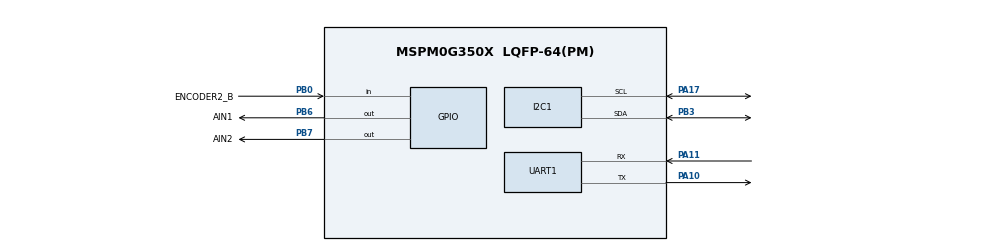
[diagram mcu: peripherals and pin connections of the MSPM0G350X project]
/**
 * @cliArgs --device "MSPM0G350X" --part "Default" --package "LQFP-64(PM)" --product "mspm0_sdk@2.05.00.05"
 * @versions {"tool":"1.24.0+4110"}
 */

/**
 * Import the modules used in this configuration.
 */
const CAPTURE  = scripting.addModule("/ti/driverlib/CAPTURE", {}, false);
const CAPTURE1 = CAPTURE.addInstance();
const CAPTURE2 = CAPTURE.addInstance();
const CAPTURE3 = CAPTURE.addInstance();
const CAPTURE4 = CAPTURE.addInstance();
const GPIO     = scripting.addModule("/ti/driverlib/GPIO", {}, false);
const GPIO1    = GPIO.addInstance();
const GPIO2    = GPIO.addInstance();
const GPIO3    = GPIO.addInstance();
const GPIO4    = GPIO.addInstance();
const GPIO5    = GPIO.addInstance();
const I2C      = scripting.addModule("/ti/driverlib/I2C", {}, false);
const I2C1     = I2C.addInstance();
const PWM      = scripting.addModule("/ti/driverlib/PWM", {}, false);
const PWM1     = PWM.addInstance();
const PWM2     = PWM.addInstance();
const SYSCTL   = scripting.addModule("/ti/driverlib/SYSCTL");
const SYSTICK  = scripting.addModule("/ti/driverlib/SYSTICK");
const TIMER    = scripting.addModule("/ti/driverlib/TIMER", {}, false);
const TIMER1   = TIMER.addInstance();
const UART     = scripting.addModule("/ti/driverlib/UART", {}, false);
const UART1    = UART.addInstance();

/**
 * Write custom configuration values to the imported modules.
 */
CAPTURE1.$name                              = "ENCODER1_A";
CAPTURE1.timerPeriod                        = "1ms";
CAPTURE1.timerStartTimer                    = true;
CAPTURE1.interrupts                         = ["CC0_DN"];
CAPTURE1.ccp0PinConfig.hideOutputInversion  = scripting.forceWrite(false);
CAPTURE1.ccp0PinConfig.onlyInternalResistor = scripting.forceWrite(false);
CAPTURE1.ccp0PinConfig.passedPeripheralType = scripting.forceWrite("Digital");
CAPTURE1.ccp0PinConfig.$name                = "ti_driverlib_gpio_GPIOPinGeneric9";

const Board = scripting.addModule("/ti/driverlib/Board", {}, false);

CAPTURE2.$name                              = "ENCODER2_A";
CAPTURE2.timerPeriod                        = "1ms";
CAPTURE2.timerStartTimer                    = true;
CAPTURE2.interrupts                         = ["CC0_DN"];
CAPTURE2.ccp0PinConfig.hideOutputInversion  = scripting.forceWrite(false);
CAPTURE2.ccp0PinConfig.onlyInternalResistor = scripting.forceWrite(false);
CAPTURE2.ccp0PinConfig.passedPeripheralType = scripting.forceWrite("Digital");
CAPTURE2.ccp0PinConfig.$name                = "ti_driverlib_gpio_GPIOPinGeneric10";

CAPTURE3.$name                              = "ENCODER3_A";
CAPTURE3.timerPeriod                        = "1ms";
CAPTURE3.timerStartTimer                    = true;
CAPTURE3.interrupts                         = ["CC0_DN"];
CAPTURE3.ccp0PinConfig.hideOutputInversion  = scripting.forceWrite(false);
CAPTURE3.ccp0PinConfig.onlyInternalResistor = scripting.forceWrite(false);
CAPTURE3.ccp0PinConfig.passedPeripheralType = scripting.forceWrite("Digital");
CAPTURE3.ccp0PinConfig.$name                = "ti_driverlib_gpio_GPIOPinGeneric11";

CAPTURE4.$name                              = "ENCODER4_A";
CAPTURE4.timerPeriod                        = "1ms";
CAPTURE4.timerStartTimer                    = true;
CAPTURE4.interrupts                         = ["CC0_DN"];
CAPTURE4.ccp0PinConfig.hideOutputInversion  = scripting.forceWrite(false);
CAPTURE4.ccp0PinConfig.onlyInternalResistor = scripting.forceWrite(false);
CAPTURE4.ccp0PinConfig.passedPeripheralType = scripting.forceWrite("Digital");
CAPTURE4.ccp0PinConfig.$name                = "ti_driverlib_gpio_GPIOPinGeneric12";

GPIO1.$name                              = "INF_INPUT";
GPIO1.port                               = "PORTA";
GPIO1.associatedPins.create(4);
GPIO1.associatedPins[0].direction        = "INPUT";
GPIO1.associatedPins[0].$name            = "L1";
GPIO1.associatedPins[0].internalResistor = "PULL_UP";
GPIO1.associatedPins[0].assignedPin      = "25";
GPIO1.associatedPins[1].$name            = "L2";
GPIO1.associatedPins[1].direction        = "INPUT";
GPIO1.associatedPins[1].internalResistor = "PULL_UP";
GPIO1.associatedPins[1].assignedPin      = "24";
GPIO1.associatedPins[2].$name            = "R2";
GPIO1.associatedPins[2].direction        = "INPUT";
GPIO1.associatedPins[2].internalResistor = "PULL_UP";
GPIO1.associatedPins[2].assignedPin      = "23";
GPIO1.associatedPins[3].$name            = "R1";
GPIO1.associatedPins[3].direction        = "INPUT";
GPIO1.associatedPins[3].internalResistor = "PULL_UP";
GPIO1.associatedPins[3].assignedPin      = "26";

GPIO2.$name                              = "LED";
GPIO2.port                               = "PORTB";
GPIO2.associatedPins[0].$name            = "LED1";
GPIO2.associatedPins[0].internalResistor = "PULL_DOWN";
GPIO2.associatedPins[0].assignedPin      = "2";

GPIO3.$name                              = "KEY";
GPIO3.port                               = "PORTA";
GPIO3.associatedPins[0].$name            = "KEY1";
GPIO3.associatedPins[0].direction        = "INPUT";
GPIO3.associatedPins[0].internalResistor = "PULL_DOWN";
GPIO3.associatedPins[0].assignedPin      = "18";

GPIO4.$name                         = "MOTORS";
GPIO4.port                          = "PORTB";
GPIO4.associatedPins.create(8);
GPIO4.associatedPins[0].$name       = "AIN1";
GPIO4.associatedPins[0].assignedPin = "6";
GPIO4.associatedPins[0].pin.$assign = "PB6";
GPIO4.associatedPins[1].$name       = "AIN2";
GPIO4.associatedPins[1].assignedPin = "7";
GPIO4.associatedPins[1].pin.$assign = "PB7";
GPIO4.associatedPins[2].$name       = "BIN1";
GPIO4.associatedPins[2].assignedPin = "8";
GPIO4.associatedPins[3].$name       = "BIN2";
GPIO4.associatedPins[3].assignedPin = "9";
GPIO4.associatedPins[4].$name       = "CIN1";
GPIO4.associatedPins[5].$name       = "CIN2";
GPIO4.associatedPins[6].$name       = "DIN1";
GPIO4.associatedPins[7].$name       = "DIN2";

GPIO5.$name                          = "GPIO_ENCODER";
GPIO5.associatedPins.create(4);
GPIO5.associatedPins[0].$name        = "ENCODER1_B";
GPIO5.associatedPins[0].direction    = "INPUT";
GPIO5.associatedPins[0].assignedPort = "PORTA";
GPIO5.associatedPins[0].assignedPin  = "7";
GPIO5.associatedPins[1].$name        = "ENCODER2_B";
GPIO5.associatedPins[1].direction    = "INPUT";
GPIO5.associatedPins[1].assignedPort = "PORTB";
GPIO5.associatedPins[1].assignedPin  = "0";
GPIO5.associatedPins[1].pin.$assign  = "PB0";
GPIO5.associatedPins[2].$name        = "ENCODER3_B";
GPIO5.associatedPins[2].direction    = "INPUT";
GPIO5.associatedPins[2].assignedPort = "PORTB";
GPIO5.associatedPins[2].assignedPin  = "18";
GPIO5.associatedPins[3].$name        = "ENCODER4_B";
GPIO5.associatedPins[3].direction    = "INPUT";
GPIO5.associatedPins[3].assignedPort = "PORTA";
GPIO5.associatedPins[3].assignedPin  = "27";

I2C1.$name                             = "I2C_SCR";
I2C1.peripheral.sdaPin.$assign         = "PB3";
I2C1.peripheral.sclPin.$assign         = "PA17";
I2C1.sdaPinConfig.hideOutputInversion  = scripting.forceWrite(false);
I2C1.sdaPinConfig.onlyInternalResistor = scripting.forceWrite(false);
I2C1.sdaPinConfig.passedPeripheralType = scripting.forceWrite("Digital");
I2C1.sdaPinConfig.$name                = "ti_driverlib_gpio_GPIOPinGeneric7";
I2C1.sclPinConfig.hideOutputInversion  = scripting.forceWrite(false);
I2C1.sclPinConfig.onlyInternalResistor = scripting.forceWrite(false);
I2C1.sclPinConfig.passedPeripheralType = scripting.forceWrite("Digital");
I2C1.sclPinConfig.$name                = "ti_driverlib_gpio_GPIOPinGeneric8";

PWM1.$name                              = "PWM_MOTOR";
PWM1.ccIndex                            = [0,1,2,3];
PWM1.timerCount                         = 3200;
PWM1.PWM_CHANNEL_0.$name                = "ti_driverlib_pwm_PWMTimerCC0";
PWM1.PWM_CHANNEL_1.$name                = "ti_driverlib_pwm_PWMTimerCC1";
PWM1.ccp0PinConfig.direction            = scripting.forceWrite("OUTPUT");
PWM1.ccp0PinConfig.hideOutputInversion  = scripting.forceWrite(false);
PWM1.ccp0PinConfig.onlyInternalResistor = scripting.forceWrite(false);
PWM1.ccp0PinConfig.passedPeripheralType = scripting.forceWrite("Digital");
PWM1.ccp0PinConfig.$name                = "ti_driverlib_gpio_GPIOPinGeneric2";
PWM1.ccp1PinConfig.direction            = scripting.forceWrite("OUTPUT");
PWM1.ccp1PinConfig.hideOutputInversion  = scripting.forceWrite(false);
PWM1.ccp1PinConfig.onlyInternalResistor = scripting.forceWrite(false);
PWM1.ccp1PinConfig.passedPeripheralType = scripting.forceWrite("Digital");
PWM1.ccp1PinConfig.$name                = "ti_driverlib_gpio_GPIOPinGeneric3";
PWM1.peripheral.$assign                 = "TIMA0";
PWM1.PWM_CHANNEL_2.$name                = "ti_driverlib_pwm_PWMTimerCC2";
PWM1.PWM_CHANNEL_3.$name                = "ti_driverlib_pwm_PWMTimerCC3";
PWM1.ccp2PinConfig.$name                = "ti_driverlib_gpio_GPIOPinGeneric4";
PWM1.ccp3PinConfig.$name                = "ti_driverlib_gpio_GPIOPinGeneric5";

PWM2.$name                              = "PWM_SERVO";
PWM2.clockDivider                       = 8;
PWM2.timerCount                         = 80000;
PWM2.ccIndex                            = [0];
PWM2.PWM_CHANNEL_0.$name                = "ti_driverlib_pwm_PWMTimerCC4";
PWM2.ccp0PinConfig.direction            = scripting.forceWrite("OUTPUT");
PWM2.ccp0PinConfig.hideOutputInversion  = scripting.forceWrite(false);
PWM2.ccp0PinConfig.onlyInternalResistor = scripting.forceWrite(false);
PWM2.ccp0PinConfig.passedPeripheralType = scripting.forceWrite("Digital");
PWM2.ccp0PinConfig.$name                = "ti_driverlib_gpio_GPIOPinGeneric6";
PWM2.peripheral.$assign                 = "TIMG12";

SYSCTL.forceDefaultClkConfig = true;

SYSTICK.periodEnable    = true;
SYSTICK.period          = 32000;
SYSTICK.interruptEnable = true;
SYSTICK.systickEnable   = true;

TIMER1.$name            = "CLOCK";
TIMER1.timerClkPrescale = 5;
TIMER1.timerMode        = "PERIODIC";
TIMER1.timerPeriod      = "10ms";
TIMER1.timerStartTimer  = true;
TIMER1.interrupts       = ["ZERO"];

UART1.$name                    = "UART_0";
UART1.targetBaudRate           = 115200;
UART1.peripheral.rxPin.$assign = "PA11";
UART1.peripheral.txPin.$assign = "PA10";
UART1.txPinConfig.$name        = "ti_driverlib_gpio_GPIOPinGeneric0";
UART1.rxPinConfig.$name        = "ti_driverlib_gpio_GPIOPinGeneric1";

/**
 * Pinmux solution for unlocked pins/peripherals. This ensures that minor changes to the automatic solver in a future
 * version of the tool will not impact the pinmux you originally saw.  These lines can be completely deleted in order to
 * re-solve from scratch.
 */
CAPTURE1.peripheral.$suggestSolution         = "TIMG8";
CAPTURE1.peripheral.ccp0Pin.$suggestSolution = "PA29";
Board.peripheral.$suggestSolution            = "DEBUGSS";
Board.peripheral.swclkPin.$suggestSolution   = "PA20";
Board.peripheral.swdioPin.$suggestSolution   = "PA19";
CAPTURE2.peripheral.$suggestSolution         = "TIMG7";
CAPTURE2.peripheral.ccp0Pin.$suggestSolution = "PA28";
CAPTURE3.peripheral.$suggestSolution         = "TIMG6";
CAPTURE3.peripheral.ccp0Pin.$suggestSolution = "PA21";
CAPTURE4.peripheral.$suggestSolution         = "TIMG0";
CAPTURE4.peripheral.ccp0Pin.$suggestSolution = "PA5";
GPIO1.associatedPins[0].pin.$suggestSolution = "PA25";
GPIO1.associatedPins[1].pin.$suggestSolution = "PA24";
GPIO1.associatedPins[2].pin.$suggestSolution = "PA23";
GPIO1.associatedPins[3].pin.$suggestSolution = "PA26";
GPIO2.associatedPins[0].pin.$suggestSolution = "PB2";
GPIO3.associatedPins[0].pin.$suggestSolution = "PA18";
GPIO4.associatedPins[2].pin.$suggestSolution = "PB8";
GPIO4.associatedPins[3].pin.$suggestSolution = "PB9";
GPIO4.associatedPins[4].pin.$suggestSolution = "PB16";
GPIO4.associatedPins[5].pin.$suggestSolution = "PB15";
GPIO4.associatedPins[6].pin.$suggestSolution = "PB14";
GPIO4.associatedPins[7].pin.$suggestSolution = "PB13";
GPIO5.associatedPins[0].pin.$suggestSolution = "PA7";
GPIO5.associatedPins[2].pin.$suggestSolution = "PB18";
GPIO5.associatedPins[3].pin.$suggestSolution = "PA27";
I2C1.peripheral.$suggestSolution             = "I2C1";
PWM1.peripheral.ccp0Pin.$suggestSolution     = "PA0";
PWM1.peripheral.ccp1Pin.$suggestSolution     = "PA1";
PWM1.peripheral.ccp2Pin.$suggestSolution     = "PA15";
PWM1.peripheral.ccp3Pin.$suggestSolution     = "PA12";
PWM2.peripheral.ccp0Pin.$suggestSolution     = "PA14";
SYSCTL.peripheral.$suggestSolution           = "SYSCTL";
TIMER1.peripheral.$suggestSolution           = "TIMA1";
UART1.peripheral.$suggestSolution            = "UART0";
